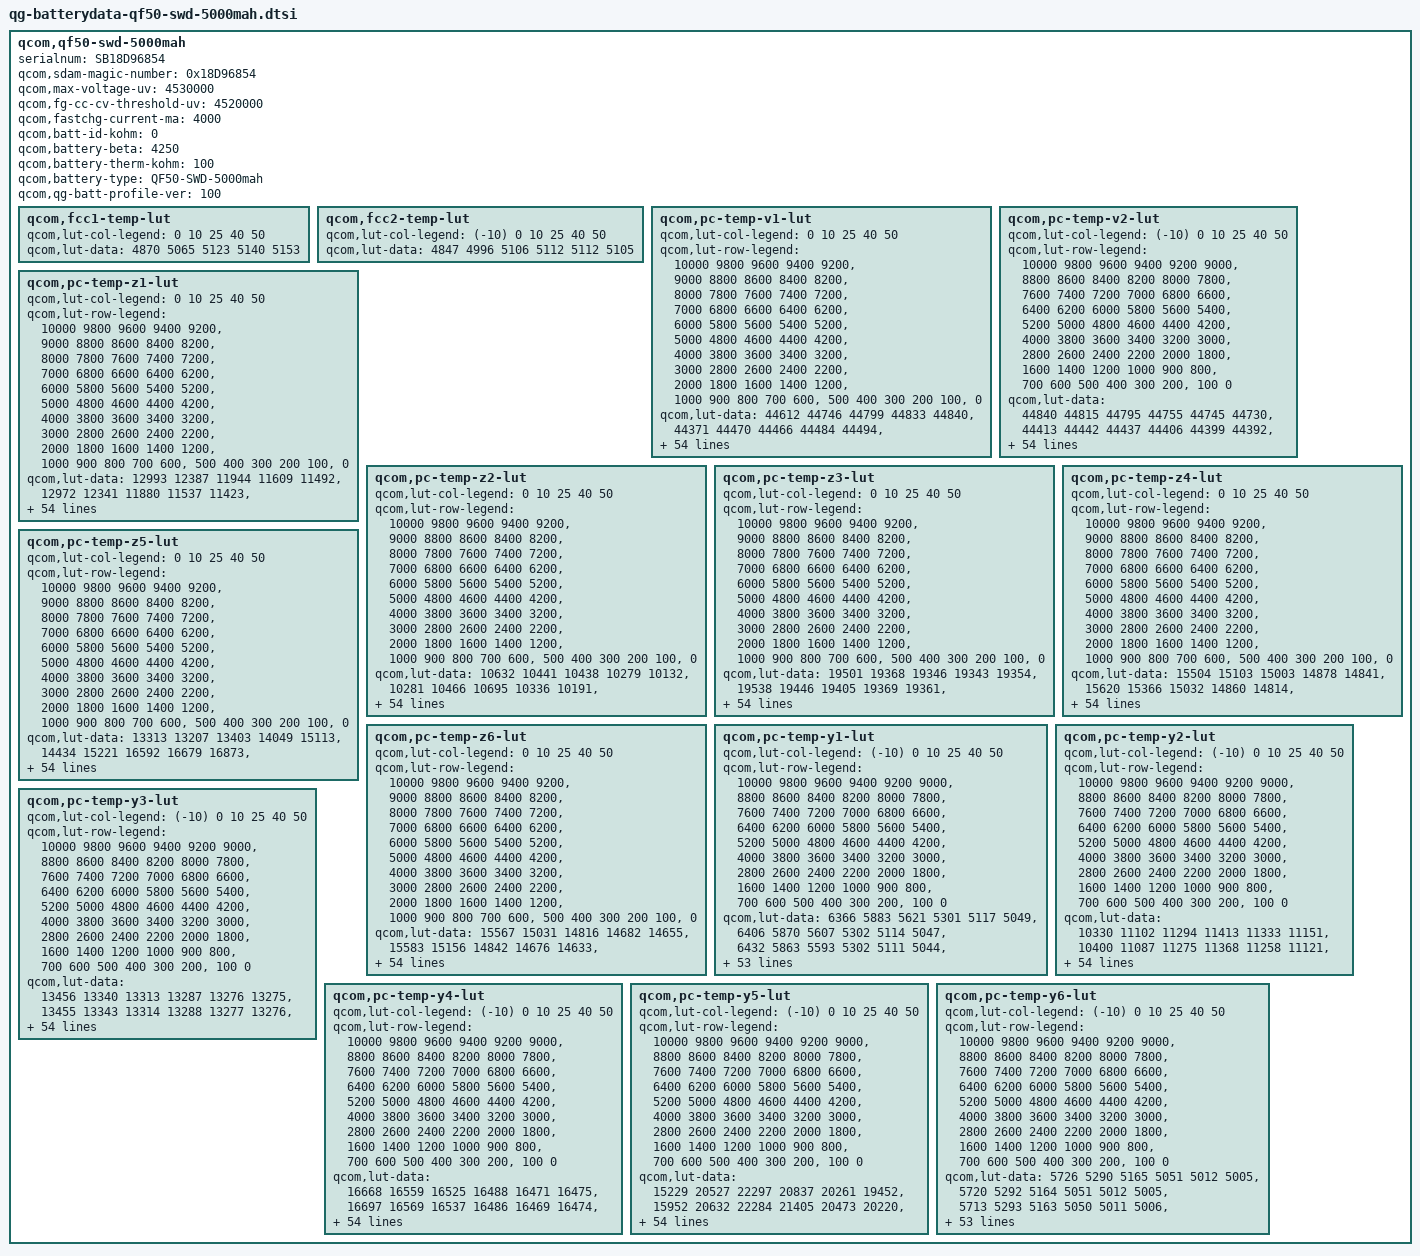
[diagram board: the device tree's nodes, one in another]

qcom,qf50-swd-5000mah {
    /* SWD_5000mAH_averaged_MasterSlave_Aug25th2023 */
    serialnum = "SB18D96854";
    qcom,sdam-magic-number = <0x18D96854>;
    qcom,max-voltage-uv = <4530000>;
    qcom,fg-cc-cv-threshold-uv = <4520000>;
    qcom,fastchg-current-ma = <4000>;
    qcom,batt-id-kohm = <0>;
    qcom,battery-beta = <4250>;
    qcom,battery-therm-kohm = <100>;
    qcom,battery-type = "QF50-SWD-5000mah";
    qcom,qg-batt-profile-ver = <100>;

	qcom,fcc1-temp-lut {
		qcom,lut-col-legend = <0 10 25 40 50>;
		qcom,lut-data = <4870 5065 5123 5140 5153>;
	};

	qcom,fcc2-temp-lut {
		qcom,lut-col-legend = <(-10) 0 10 25 40 50>;
		qcom,lut-data = <4847 4996 5106 5112 5112 5105>;
	};

	qcom,pc-temp-v1-lut {
		qcom,lut-col-legend = <0 10 25 40 50>;
		qcom,lut-row-legend = <10000 9800 9600 9400 9200>,
			<9000 8800 8600 8400 8200>,
			<8000 7800 7600 7400 7200>,
			<7000 6800 6600 6400 6200>,
			<6000 5800 5600 5400 5200>,
			<5000 4800 4600 4400 4200>,
			<4000 3800 3600 3400 3200>,
			<3000 2800 2600 2400 2200>,
			<2000 1800 1600 1400 1200>,
			<1000 900 800 700 600>,
			<500 400 300 200 100>,
			<0>;
		qcom,lut-data = <44612 44746 44799 44833 44840>,
			<44371 44470 44466 44484 44494>,
			<44146 44243 44222 44230 44237>,
			<43933 44027 44008 44012 44016>,
			<43716 43809 43792 43796 43800>,
			<43493 43592 43573 43580 43583>,
			<43265 43364 43348 43361 43363>,
			<43029 43123 43110 43127 43132>,
			<42785 42875 42862 42882 42891>,
			<42539 42623 42613 42633 42645>,
			<42294 42368 42359 42381 42393>,
			<42051 42118 42107 42129 42141>,
			<41813 41870 41857 41880 41891>,
			<41579 41627 41610 41632 41644>,
			<41353 41391 41373 41393 41405>,
			<41136 41161 41142 41158 41175>,
			<40927 40943 40918 40933 40950>,
			<40725 40736 40704 40719 40732>,
			<40532 40536 40499 40515 40521>,
			<40342 40344 40308 40322 40324>,
			<40160 40155 40130 40143 40144>,
			<39983 39958 39929 39944 39947>,
			<39793 39754 39680 39695 39700>,
			<39575 39537 39431 39444 39447>,
			<39354 39273 39217 39243 39253>,
			<39161 39028 39024 39069 39091>,
			<38983 38889 38886 38930 38950>,
			<38844 38795 38790 38819 38828>,
			<38746 38709 38704 38720 38717>,
			<38666 38620 38615 38620 38610>,
			<38591 38538 38530 38525 38511>,
			<38521 38461 38451 38438 38422>,
			<38458 38389 38377 38359 38346>,
			<38397 38324 38308 38285 38273>,
			<38341 38269 38245 38214 38202>,
			<38292 38218 38185 38146 38133>,
			<38253 38174 38129 38080 38061>,
			<38212 38134 38076 38016 37986>,
			<38164 38079 38010 37938 37898>,
			<38110 37995 37919 37833 37782>,
			<38037 37892 37811 37714 37650>,
			<37921 37771 37691 37597 37526>,
			<37788 37628 37551 37474 37397>,
			<37644 37458 37384 37313 37226>,
			<37482 37291 37222 37161 37079>,
			<37312 37169 37112 37064 37002>,
			<37238 37133 37076 37029 36971>,
			<37190 37103 37051 37005 36947>,
			<37144 37084 37029 36981 36923>,
			<37101 37047 36979 36924 36862>,
			<37066 36883 36754 36670 36593>,
			<37015 36451 36315 36222 36146>,
			<36854 35859 35711 35630 35559>,
			<36396 35022 34877 34819 34756>,
			<35545 33646 33564 33548 33505>,
			<30000 30000 30000 30000 30000>;
	};

	qcom,pc-temp-v2-lut {
		qcom,lut-col-legend = <(-10) 0 10 25 40 50>;
		qcom,lut-row-legend = <10000 9800 9600 9400 9200 9000>,
			<8800 8600 8400 8200 8000 7800>,
			<7600 7400 7200 7000 6800 6600>,
			<6400 6200 6000 5800 5600 5400>,
			<5200 5000 4800 4600 4400 4200>,
			<4000 3800 3600 3400 3200 3000>,
			<2800 2600 2400 2200 2000 1800>,
			<1600 1400 1200 1000 900 800>,
			<700 600 500 400 300 200>,
			<100 0>;
		qcom,lut-data = <44840 44815 44795 44755 44745 44730>,
			<44413 44442 44437 44406 44399 44392>,
			<44048 44119 44125 44100 44094 44091>,
			<43764 43861 43871 43845 43837 43837>,
			<43545 43657 43664 43634 43622 43622>,
			<43342 43455 43455 43420 43405 43407>,
			<43123 43234 43227 43189 43174 43178>,
			<42904 43008 42992 42951 42938 42943>,
			<42681 42772 42750 42705 42694 42699>,
			<42451 42524 42497 42452 42443 42446>,
			<42219 42276 42245 42198 42192 42194>,
			<41989 42030 41993 41946 41942 41944>,
			<41758 41785 41743 41696 41693 41697>,
			<41531 41545 41498 41453 41451 41456>,
			<41310 41310 41257 41215 41215 41223>,
			<41090 41081 41023 40983 40986 40994>,
			<40863 40865 40794 40758 40762 40770>,
			<40630 40653 40576 40541 40547 40554>,
			<40392 40429 40377 40338 40345 40349>,
			<40142 40191 40185 40141 40149 40151>,
			<39888 39946 39961 39941 39959 39961>,
			<39653 39687 39688 39741 39776 39783>,
			<39432 39430 39425 39529 39578 39590>,
			<39226 39211 39194 39275 39318 39338>,
			<39035 39017 38985 39021 39050 39072>,
			<38857 38846 38812 38837 38865 38884>,
			<38691 38693 38666 38696 38728 38745>,
			<38529 38556 38535 38572 38608 38622>,
			<38384 38426 38414 38461 38496 38507>,
			<38273 38305 38303 38360 38395 38402>,
			<38183 38195 38203 38265 38303 38309>,
			<38104 38094 38112 38176 38218 38224>,
			<38032 38003 38028 38094 38140 38144>,
			<37966 37927 37947 38021 38071 38072>,
			<37902 37864 37872 37951 38001 37998>,
			<37842 37808 37809 37880 37914 37904>,
			<37779 37760 37753 37809 37818 37794>,
			<37715 37716 37692 37729 37718 37683>,
			<37649 37659 37628 37637 37613 37572>,
			<37577 37592 37553 37540 37508 37462>,
			<37500 37509 37454 37445 37412 37367>,
			<37417 37393 37331 37343 37312 37271>,
			<37323 37255 37187 37213 37189 37148>,
			<37217 37114 37011 37067 37048 37001>,
			<37105 36960 36831 36924 36918 36868>,
			<36988 36795 36716 36861 36869 36821>,
			<36929 36726 36671 36841 36856 36808>,
			<36869 36669 36617 36820 36840 36791>,
			<36809 36612 36540 36784 36811 36761>,
			<36738 36515 36406 36703 36731 36673>,
			<36645 36346 36058 36414 36427 36347>,
			<36518 36138 35405 35887 35912 35836>,
			<36354 35618 34645 35179 35234 35164>,
			<36108 35142 33700 34152 34279 34213>,
			<35860 34625 32415 32677 32858 32764>,
			<35905 33809 29152 28152 28264 28690>;
	};

	qcom,pc-temp-z1-lut {
		qcom,lut-col-legend = <0 10 25 40 50>;
		qcom,lut-row-legend = <10000 9800 9600 9400 9200>,
			<9000 8800 8600 8400 8200>,
			<8000 7800 7600 7400 7200>,
			<7000 6800 6600 6400 6200>,
			<6000 5800 5600 5400 5200>,
			<5000 4800 4600 4400 4200>,
			<4000 3800 3600 3400 3200>,
			<3000 2800 2600 2400 2200>,
			<2000 1800 1600 1400 1200>,
			<1000 900 800 700 600>,
			<500 400 300 200 100>,
			<0>;
		qcom,lut-data = <12993 12387 11944 11609 11492>,
			<12972 12341 11880 11537 11423>,
			<12947 12311 11855 11516 11404>,
			<12920 12290 11826 11502 11393>,
			<12896 12267 11806 11491 11386>,
			<12866 12245 11792 11480 11379>,
			<12831 12225 11780 11471 11373>,
			<12806 12207 11767 11463 11370>,
			<12788 12190 11753 11457 11368>,
			<12770 12173 11743 11453 11367>,
			<12749 12157 11733 11452 11365>,
			<12729 12141 11727 11450 11364>,
			<12709 12124 11723 11448 11363>,
			<12685 12114 11721 11446 11362>,
			<12669 12114 11721 11446 11362>,
			<12665 12115 11723 11446 11362>,
			<12662 12116 11724 11446 11363>,
			<12658 12117 11725 11446 11364>,
			<12644 12118 11725 11448 11365>,
			<12635 12118 11726 11449 11367>,
			<12643 12118 11729 11451 11368>,
			<12664 12121 11731 11453 11369>,
			<12674 12129 11732 11453 11370>,
			<12675 12136 11734 11454 11371>,
			<12676 12144 11738 11455 11372>,
			<12680 12150 11744 11458 11374>,
			<12686 12150 11749 11461 11377>,
			<12690 12147 11752 11463 11379>,
			<12695 12145 11755 11466 11382>,
			<12700 12150 11760 11469 11385>,
			<12705 12158 11768 11473 11388>,
			<12717 12166 11774 11477 11391>,
			<12725 12175 11781 11482 11394>,
			<12715 12179 11787 11486 11397>,
			<12701 12180 11793 11492 11402>,
			<12701 12181 11798 11498 11407>,
			<12732 12187 11804 11504 11411>,
			<12761 12200 11809 11510 11415>,
			<12766 12213 11815 11516 11419>,
			<12766 12229 11823 11521 11424>,
			<12770 12241 11833 11527 11429>,
			<12786 12249 11844 11533 11432>,
			<12806 12257 11857 11539 11436>,
			<12832 12267 11866 11544 11439>,
			<12858 12284 11877 11551 11444>,
			<12851 12297 11881 11555 11446>,
			<12859 12284 11887 11555 11446>,
			<12862 12300 11898 11555 11447>,
			<12840 12296 11898 11559 11449>,
			<12864 12289 11901 11564 11453>,
			<12849 12305 11907 11570 11458>,
			<12880 12327 11922 11575 11462>,
			<12870 12331 11928 11582 11468>,
			<12924 12349 11941 11595 11479>,
			<12924 12349 11941 11595 11479>,
			<12924 12349 11941 11595 11479>;
	};

	qcom,pc-temp-z2-lut {
		qcom,lut-col-legend = <0 10 25 40 50>;
		qcom,lut-row-legend = <10000 9800 9600 9400 9200>,
			<9000 8800 8600 8400 8200>,
			<8000 7800 7600 7400 7200>,
			<7000 6800 6600 6400 6200>,
			<6000 5800 5600 5400 5200>,
			<5000 4800 4600 4400 4200>,
			<4000 3800 3600 3400 3200>,
			<3000 2800 2600 2400 2200>,
			<2000 1800 1600 1400 1200>,
			<1000 900 800 700 600>,
			<500 400 300 200 100>,
			<0>;
		qcom,lut-data = <10632 10441 10438 10279 10132>,
			<10281 10466 10695 10336 10191>,
			<10369 10561 10727 10521 10298>,
			<10428 10621 10695 10573 10465>,
			<10448 10605 10657 10589 10557>,
			<10429 10563 10610 10523 10527>,
			<10401 10527 10560 10432 10469>,
			<10381 10499 10512 10389 10411>,
			<10363 10475 10465 10358 10344>,
			<10347 10449 10433 10339 10316>,
			<10334 10427 10403 10322 10314>,
			<10324 10424 10389 10313 10313>,
			<10323 10433 10395 10324 10316>,
			<10325 10444 10407 10345 10323>,
			<10330 10454 10417 10350 10313>,
			<10343 10466 10427 10350 10246>,
			<10365 10536 10437 10349 10195>,
			<10382 10770 10446 10324 10203>,
			<10394 10892 10455 10288 10224>,
			<10404 10737 10464 10284 10245>,
			<10414 10544 10474 10297 10272>,
			<10424 10527 10497 10323 10312>,
			<10435 10537 10608 10510 10437>,
			<10447 10545 10708 10704 10572>,
			<10458 10555 10657 10632 10554>,
			<10467 10563 10523 10398 10443>,
			<10476 10559 10468 10317 10406>,
			<10480 10549 10467 10346 10623>,
			<10476 10546 10480 10384 10853>,
			<10472 10550 10507 10448 10888>,
			<10471 10555 10546 10548 10863>,
			<10474 10559 10575 10578 10754>,
			<10477 10564 10601 10556 10524>,
			<10482 10567 10617 10514 10344>,
			<10489 10568 10612 10438 10267>,
			<10494 10570 10599 10356 10213>,
			<10496 10573 10596 10342 10216>,
			<10497 10580 10596 10355 10274>,
			<10499 10588 10602 10378 10341>,
			<10501 10600 10635 10488 10399>,
			<10502 10607 10670 10599 10470>,
			<10502 10606 10682 10584 10606>,
			<10502 10603 10688 10538 10774>,
			<10508 10600 10671 10553 10717>,
			<10657 10649 10680 10556 10560>,
			<10620 10719 10674 10501 10432>,
			<10581 10706 10686 10490 10408>,
			<10554 10702 10650 10495 10411>,
			<10491 11125 10592 10515 10435>,
			<10392 11228 10633 10595 10526>,
			<10295 11060 10635 10516 10442>,
			<10109 10728 10652 10316 10170>,
			<9992 10608 10570 10203 10082>,
			<10053 10499 10489 10143 10022>,
			<10053 10499 10489 10143 10022>,
			<10053 10499 10489 10143 10022>;
	};

	qcom,pc-temp-z3-lut {
		qcom,lut-col-legend = <0 10 25 40 50>;
		qcom,lut-row-legend = <10000 9800 9600 9400 9200>,
			<9000 8800 8600 8400 8200>,
			<8000 7800 7600 7400 7200>,
			<7000 6800 6600 6400 6200>,
			<6000 5800 5600 5400 5200>,
			<5000 4800 4600 4400 4200>,
			<4000 3800 3600 3400 3200>,
			<3000 2800 2600 2400 2200>,
			<2000 1800 1600 1400 1200>,
			<1000 900 800 700 600>,
			<500 400 300 200 100>,
			<0>;
		qcom,lut-data = <19501 19368 19346 19343 19354>,
			<19538 19446 19405 19369 19361>,
			<19572 19482 19428 19395 19384>,
			<19609 19501 19437 19404 19393>,
			<19626 19508 19442 19408 19398>,
			<19632 19512 19447 19410 19402>,
			<19636 19514 19450 19412 19405>,
			<19636 19516 19452 19415 19406>,
			<19632 19516 19454 19418 19407>,
			<19629 19514 19452 19418 19408>,
			<19626 19509 19444 19413 19404>,
			<19623 19503 19435 19406 19398>,
			<19620 19495 19430 19402 19395>,
			<19616 19488 19425 19399 19392>,
			<19612 19484 19420 19395 19387>,
			<19604 19481 19414 19391 19381>,
			<19592 19481 19409 19387 19375>,
			<19585 19487 19405 19380 19370>,
			<19582 19490 19402 19373 19367>,
			<19579 19480 19398 19367 19362>,
			<19575 19468 19394 19360 19355>,
			<19572 19468 19393 19358 19352>,
			<19571 19471 19404 19364 19353>,
			<19580 19475 19415 19370 19356>,
			<19590 19479 19411 19364 19350>,
			<19593 19482 19398 19345 19333>,
			<19594 19481 19390 19337 19327>,
			<19594 19474 19385 19337 19350>,
			<19592 19471 19382 19339 19375>,
			<19587 19470 19383 19348 19386>,
			<19584 19471 19386 19364 19402>,
			<19580 19472 19390 19372 19402>,
			<19577 19474 19397 19377 19391>,
			<19576 19474 19401 19378 19380>,
			<19575 19473 19403 19374 19369>,
			<19574 19472 19405 19369 19357>,
			<19572 19470 19402 19363 19349>,
			<19569 19467 19396 19354 19340>,
			<19565 19464 19391 19350 19337>,
			<19560 19460 19389 19351 19336>,
			<19555 19456 19387 19352 19336>,
			<19550 19453 19384 19351 19338>,
			<19544 19450 19381 19350 19342>,
			<19532 19447 19378 19351 19351>,
			<19439 19435 19372 19351 19354>,
			<19401 19419 19364 19339 19341>,
			<19399 19412 19364 19337 19336>,
			<19322 19412 19361 19334 19325>,
			<19313 19316 19352 19327 19320>,
			<19311 19305 19347 19320 19310>,
			<19295 19319 19353 19336 19330>,
			<19284 19396 19349 19361 19351>,
			<19285 19383 19361 19364 19352>,
			<19334 19426 19382 19360 19350>,
			<19334 19426 19382 19360 19350>,
			<19334 19426 19382 19360 19350>;
	};

	qcom,pc-temp-z4-lut {
		qcom,lut-col-legend = <0 10 25 40 50>;
		qcom,lut-row-legend = <10000 9800 9600 9400 9200>,
			<9000 8800 8600 8400 8200>,
			<8000 7800 7600 7400 7200>,
			<7000 6800 6600 6400 6200>,
			<6000 5800 5600 5400 5200>,
			<5000 4800 4600 4400 4200>,
			<4000 3800 3600 3400 3200>,
			<3000 2800 2600 2400 2200>,
			<2000 1800 1600 1400 1200>,
			<1000 900 800 700 600>,
			<500 400 300 200 100>,
			<0>;
		qcom,lut-data = <15504 15103 15003 14878 14841>,
			<15620 15366 15032 14860 14814>,
			<15555 15260 15065 14909 14873>,
			<15384 15127 14993 14876 14847>,
			<15235 15041 14935 14843 14819>,
			<15133 14968 14892 14819 14800>,
			<15049 14910 14855 14798 14782>,
			<14985 14863 14823 14776 14765>,
			<14935 14826 14795 14756 14747>,
			<14893 14797 14772 14741 14735>,
			<14858 14774 14751 14731 14728>,
			<14827 14755 14736 14722 14723>,
			<14802 14737 14726 14715 14719>,
			<14780 14725 14719 14709 14716>,
			<14763 14719 14712 14704 14712>,
			<14751 14713 14705 14699 14709>,
			<14741 14703 14699 14694 14705>,
			<14736 14682 14694 14690 14702>,
			<14731 14672 14689 14686 14698>,
			<14729 14679 14684 14681 14693>,
			<14727 14690 14679 14675 14686>,
			<14725 14696 14679 14673 14683>,
			<14725 14703 14706 14704 14714>,
			<14739 14715 14746 14751 14764>,
			<14761 14762 14788 14789 14795>,
			<14780 14812 14832 14825 14820>,
			<14801 14813 14842 14834 14826>,
			<14809 14796 14829 14822 14791>,
			<14804 14779 14812 14803 14749>,
			<14795 14765 14796 14779 14726>,
			<14786 14752 14779 14749 14698>,
			<14778 14742 14761 14728 14686>,
			<14770 14733 14742 14708 14682>,
			<14765 14728 14726 14693 14678>,
			<14761 14724 14714 14684 14674>,
			<14757 14721 14704 14678 14670>,
			<14753 14718 14700 14675 14668>,
			<14747 14713 14698 14673 14666>,
			<14739 14710 14698 14673 14666>,
			<14727 14707 14701 14684 14680>,
			<14717 14703 14705 14695 14698>,
			<14708 14695 14703 14694 14694>,
			<14698 14684 14697 14688 14681>,
			<14683 14675 14694 14689 14685>,
			<14717 14659 14683 14684 14684>,
			<14756 14646 14665 14667 14660>,
			<14751 14644 14656 14664 14657>,
			<14832 14639 14644 14655 14652>,
			<14851 14740 14635 14634 14633>,
			<14849 14749 14633 14625 14625>,
			<14862 14735 14650 14649 14654>,
			<14873 14662 14671 14648 14661>,
			<14874 14686 14663 14652 14669>,
			<14850 14663 14649 14661 14676>,
			<14850 14663 14649 14661 14676>,
			<14850 14663 14649 14661 14676>;
	};

	qcom,pc-temp-z5-lut {
		qcom,lut-col-legend = <0 10 25 40 50>;
		qcom,lut-row-legend = <10000 9800 9600 9400 9200>,
			<9000 8800 8600 8400 8200>,
			<8000 7800 7600 7400 7200>,
			<7000 6800 6600 6400 6200>,
			<6000 5800 5600 5400 5200>,
			<5000 4800 4600 4400 4200>,
			<4000 3800 3600 3400 3200>,
			<3000 2800 2600 2400 2200>,
			<2000 1800 1600 1400 1200>,
			<1000 900 800 700 600>,
			<500 400 300 200 100>,
			<0>;
		qcom,lut-data = <13313 13207 13403 14049 15113>,
			<14434 15221 16592 16679 16873>,
			<15579 16599 17326 18067 18406>,
			<16715 17702 18125 19412 20281>,
			<17677 18476 18828 20393 21932>,
			<18518 19101 19382 20776 22942>,
			<19301 19868 19953 21148 23811>,
			<20019 20868 20728 22131 24878>,
			<20654 21829 21588 23632 26093>,
			<21393 22590 22245 24453 27076>,
			<22382 23273 22787 24989 27766>,
			<23549 24010 23336 25518 28394>,
			<24913 24929 24049 26271 29251>,
			<26962 25887 24806 27310 30194>,
			<28687 26681 25369 28456 30440>,
			<29334 27595 25890 29981 30240>,
			<29780 29937 26577 30962 30080>,
			<30324 35286 27858 31117 30991>,
			<31175 38212 29326 31196 32964>,
			<32065 36045 30261 31516 34713>,
			<32719 33235 31002 32338 36585>,
			<33376 34280 32794 33669 37422>,
			<34767 38251 43035 37493 37210>,
			<41528 41221 52368 41043 36676>,
			<48963 42862 47679 37077 32995>,
			<50242 43703 34918 25108 22664>,
			<49361 41565 28153 19588 18294>,
			<47961 35696 24825 18270 23040>,
			<45052 32668 23149 17696 28049>,
			<41893 32300 22989 19075 30762>,
			<41053 32506 23158 22191 35952>,
			<40746 33846 23952 23569 36677>,
			<40612 36812 26794 25459 35218>,
			<41448 39316 29967 27516 33611>,
			<43144 41515 34224 29770 31726>,
			<43668 42904 38322 31839 29972>,
			<43439 42967 39152 32309 29685>,
			<43114 42837 39090 32395 29773>,
			<42950 42667 38697 32615 29880>,
			<42923 42224 37751 34307 30085>,
			<42900 41653 36280 36065 30335>,
			<42849 40988 33786 33327 30345>,
			<42200 40309 30670 27249 30206>,
			<37984 40105 29474 27643 33552>,
			<27139 41604 29960 28411 36016>,
			<22167 39519 28888 24202 27578>,
			<27306 32777 30845 22823 23364>,
			<12627 32219 31255 22619 20396>,
			<12221 13721 27976 25098 23600>,
			<12190 12661 25949 25258 23098>,
			<11797 13341 24861 26244 26281>,
			<11620 22722 18709 28100 24475>,
			<11663 20909 21549 25076 20767>,
			<12783 31145 26214 19730 17364>,
			<12783 31145 26214 19730 17364>,
			<12783 31145 26214 19730 17364>;
	};

	qcom,pc-temp-z6-lut {
		qcom,lut-col-legend = <0 10 25 40 50>;
		qcom,lut-row-legend = <10000 9800 9600 9400 9200>,
			<9000 8800 8600 8400 8200>,
			<8000 7800 7600 7400 7200>,
			<7000 6800 6600 6400 6200>,
			<6000 5800 5600 5400 5200>,
			<5000 4800 4600 4400 4200>,
			<4000 3800 3600 3400 3200>,
			<3000 2800 2600 2400 2200>,
			<2000 1800 1600 1400 1200>,
			<1000 900 800 700 600>,
			<500 400 300 200 100>,
			<0>;
		qcom,lut-data = <15567 15031 14816 14682 14655>,
			<15583 15156 14842 14676 14633>,
			<15553 15108 14860 14705 14665>,
			<15464 15047 14828 14693 14657>,
			<15383 15002 14801 14681 14649>,
			<15321 14962 14781 14670 14642>,
			<15267 14928 14763 14661 14635>,
			<15223 14901 14747 14652 14629>,
			<15184 14877 14733 14645 14622>,
			<15151 14856 14718 14637 14616>,
			<15121 14838 14703 14629 14611>,
			<15095 14822 14691 14622 14605>,
			<15072 14807 14683 14617 14601>,
			<15051 14796 14677 14612 14598>,
			<15034 14790 14670 14607 14593>,
			<15018 14785 14664 14602 14588>,
			<15005 14780 14659 14597 14583>,
			<14998 14775 14654 14591 14579>,
			<14994 14772 14650 14586 14575>,
			<14992 14770 14646 14580 14570>,
			<14992 14769 14642 14574 14563>,
			<14992 14770 14642 14572 14560>,
			<14992 14776 14660 14590 14576>,
			<15004 14785 14684 14613 14599>,
			<15022 14809 14699 14623 14605>,
			<15035 14833 14712 14630 14609>,
			<15046 14833 14714 14632 14609>,
			<15050 14825 14707 14627 14607>,
			<15048 14818 14699 14621 14603>,
			<15045 14813 14694 14616 14600>,
			<15042 14809 14689 14613 14597>,
			<15039 14807 14685 14608 14592>,
			<15037 14806 14681 14603 14586>,
			<15036 14805 14679 14598 14579>,
			<15036 14805 14676 14593 14572>,
			<15036 14804 14674 14589 14565>,
			<15037 14804 14672 14584 14559>,
			<15038 14805 14669 14580 14555>,
			<15040 14806 14669 14578 14553>,
			<15042 14807 14671 14583 14559>,
			<15044 14808 14674 14589 14566>,
			<15047 14807 14674 14589 14566>,
			<15049 14806 14672 14587 14566>,
			<15051 14807 14672 14589 14571>,
			<15039 14802 14668 14588 14572>,
			<15043 14794 14660 14575 14555>,
			<15045 14789 14656 14573 14551>,
			<15039 14788 14650 14566 14544>,
			<15044 14784 14642 14555 14533>,
			<15047 14787 14642 14548 14524>,
			<15045 14793 14656 14568 14547>,
			<15052 14808 14666 14583 14565>,
			<15069 14818 14674 14589 14571>,
			<15089 14842 14686 14594 14577>,
			<15089 14842 14686 14594 14577>,
			<15089 14842 14686 14594 14577>;
	};

	qcom,pc-temp-y1-lut {
		qcom,lut-col-legend = <(-10) 0 10 25 40 50>;
		qcom,lut-row-legend = <10000 9800 9600 9400 9200 9000>,
			<8800 8600 8400 8200 8000 7800>,
			<7600 7400 7200 7000 6800 6600>,
			<6400 6200 6000 5800 5600 5400>,
			<5200 5000 4800 4600 4400 4200>,
			<4000 3800 3600 3400 3200 3000>,
			<2800 2600 2400 2200 2000 1800>,
			<1600 1400 1200 1000 900 800>,
			<700 600 500 400 300 200>,
			<100 0>;
		qcom,lut-data = <6366 5883 5621 5301 5117 5049>,
			<6406 5870 5607 5302 5114 5047>,
			<6432 5863 5593 5302 5111 5044>,
			<6447 5861 5582 5300 5108 5042>,
			<6453 5861 5573 5297 5105 5040>,
			<6452 5864 5571 5294 5102 5038>,
			<6443 5873 5574 5289 5099 5037>,
			<6423 5884 5578 5283 5096 5035>,
			<6404 5885 5575 5279 5093 5034>,
			<6386 5874 5563 5274 5090 5033>,
			<6372 5865 5556 5270 5088 5032>,
			<6372 5856 5557 5266 5087 5031>,
			<6377 5846 5559 5263 5085 5031>,
			<6380 5845 5557 5261 5084 5031>,
			<6378 5851 5554 5260 5083 5031>,
			<6377 5854 5550 5259 5082 5031>,
			<6382 5852 5540 5259 5084 5031>,
			<6404 5848 5532 5260 5085 5031>,
			<6418 5848 5534 5260 5085 5031>,
			<6412 5850 5538 5260 5084 5032>,
			<6401 5852 5541 5261 5084 5033>,
			<6392 5865 5544 5263 5085 5034>,
			<6383 5883 5546 5266 5086 5035>,
			<6377 5884 5546 5269 5088 5036>,
			<6379 5875 5546 5272 5091 5037>,
			<6384 5869 5546 5276 5093 5039>,
			<6389 5871 5547 5282 5095 5040>,
			<6391 5876 5549 5286 5097 5042>,
			<6393 5878 5552 5288 5100 5044>,
			<6387 5880 5557 5290 5102 5046>,
			<6369 5883 5561 5294 5105 5049>,
			<6359 5884 5564 5300 5108 5051>,
			<6370 5885 5567 5306 5111 5053>,
			<6387 5887 5571 5312 5115 5056>,
			<6390 5891 5574 5319 5118 5058>,
			<6388 5892 5576 5323 5121 5061>,
			<6386 5889 5578 5327 5124 5063>,
			<6379 5882 5581 5330 5126 5065>,
			<6368 5879 5590 5333 5128 5067>,
			<6360 5878 5599 5335 5130 5068>,
			<6360 5879 5608 5337 5133 5070>,
			<6362 5885 5618 5339 5136 5072>,
			<6365 5891 5618 5341 5137 5073>,
			<6364 5900 5618 5350 5139 5074>,
			<6358 5902 5630 5354 5143 5078>,
			<6367 5894 5633 5364 5149 5081>,
			<6389 5922 5626 5367 5149 5081>,
			<6423 5930 5658 5379 5148 5080>,
			<6468 5997 5634 5375 5149 5081>,
			<6540 6066 5705 5380 5149 5082>,
			<6619 6074 5776 5384 5150 5083>,
			<6696 5962 5736 5393 5156 5088>,
			<6846 5943 5589 5420 5164 5093>,
			<7079 5943 5285 5458 5172 5101>,
			<7079 5943 5285 5458 5172 5101>,
			<7079 5943 5285 5458 5172 5101>;
	};

	qcom,pc-temp-y2-lut {
		qcom,lut-col-legend = <(-10) 0 10 25 40 50>;
		qcom,lut-row-legend = <10000 9800 9600 9400 9200 9000>,
			<8800 8600 8400 8200 8000 7800>,
			<7600 7400 7200 7000 6800 6600>,
			<6400 6200 6000 5800 5600 5400>,
			<5200 5000 4800 4600 4400 4200>,
			<4000 3800 3600 3400 3200 3000>,
			<2800 2600 2400 2200 2000 1800>,
			<1600 1400 1200 1000 900 800>,
			<700 600 500 400 300 200>,
			<100 0>;
		qcom,lut-data = <10330 11102 11294 11413 11333 11151>,
			<10400 11087 11275 11368 11258 11121>,
			<10474 11072 11253 11323 11162 11089>,
			<10546 11057 11229 11278 11064 11053>,
			<10607 11044 11204 11235 10982 11017>,
			<10652 11031 11177 11194 10935 10980>,
			<10678 11019 11148 11151 10907 10940>,
			<10696 11007 11119 11112 10887 10900>,
			<10710 10993 11094 11080 10882 10862>,
			<10720 10974 11072 11049 10876 10824>,
			<10729 10965 11061 11039 10871 10792>,
			<10742 10967 11059 11058 10857 10763>,
			<10759 10974 11059 11082 10844 10743>,
			<10780 10986 11068 11096 10850 10743>,
			<10809 11012 11092 11110 10870 10751>,
			<10841 11043 11118 11133 10886 10756>,
			<10869 11076 11149 11180 10897 10759>,
			<10897 11109 11187 11232 10914 10764>,
			<10914 11128 11243 11288 10950 10787>,
			<10919 11145 11305 11347 11018 10844>,
			<10922 11153 11315 11376 11137 10945>,
			<10923 11158 11286 11404 11403 11188>,
			<10917 11169 11266 11419 11561 11344>,
			<10909 11180 11277 11366 11412 11270>,
			<10898 11193 11300 11284 11185 11146>,
			<10880 11205 11321 11272 11147 11118>,
			<10858 11218 11347 11280 11147 11119>,
			<10831 11230 11359 11292 11149 11126>,
			<10785 11230 11360 11327 11201 11156>,
			<10597 11219 11360 11377 11269 11208>,
			<10114 11210 11366 11424 11288 11266>,
			<9821 11205 11385 11471 11295 11339>,
			<9776 11197 11392 11508 11320 11380>,
			<9750 11162 11379 11538 11425 11403>,
			<9730 11041 11355 11556 11520 11418>,
			<9713 10958 11329 11549 11491 11408>,
			<9701 10949 11291 11528 11401 11379>,
			<9692 10945 11249 11505 11353 11347>,
			<9685 10911 11204 11470 11328 11264>,
			<9680 10836 11146 11444 11312 11183>,
			<9675 10714 11056 11445 11319 11169>,
			<9671 10271 10934 11448 11325 11173>,
			<9668 9814 10803 11385 11258 11167>,
			<9666 9724 10441 11338 11204 11125>,
			<9663 9688 10088 11206 11146 10981>,
			<9660 9672 9889 11157 10973 10822>,
			<9658 9664 9757 11187 10959 10801>,
			<9656 9658 9689 11206 11004 10785>,
			<9653 9651 9662 11215 11035 10831>,
			<9650 9649 9652 11212 11033 10867>,
			<9649 9648 9650 11090 10896 10750>,
			<9648 9648 9649 10944 10858 10703>,
			<9648 9648 9649 10736 10735 10610>,
			<9648 9649 9649 10355 10628 10470>,
			<9648 9649 9649 10355 10628 10470>,
			<9648 9649 9649 10355 10628 10470>;
	};

	qcom,pc-temp-y3-lut {
		qcom,lut-col-legend = <(-10) 0 10 25 40 50>;
		qcom,lut-row-legend = <10000 9800 9600 9400 9200 9000>,
			<8800 8600 8400 8200 8000 7800>,
			<7600 7400 7200 7000 6800 6600>,
			<6400 6200 6000 5800 5600 5400>,
			<5200 5000 4800 4600 4400 4200>,
			<4000 3800 3600 3400 3200 3000>,
			<2800 2600 2400 2200 2000 1800>,
			<1600 1400 1200 1000 900 800>,
			<700 600 500 400 300 200>,
			<100 0>;
		qcom,lut-data = <13456 13340 13313 13287 13276 13275>,
			<13455 13343 13314 13288 13277 13276>,
			<13454 13346 13315 13289 13278 13277>,
			<13453 13349 13316 13290 13279 13278>,
			<13451 13351 13317 13291 13280 13279>,
			<13450 13353 13318 13292 13281 13280>,
			<13449 13355 13319 13294 13282 13281>,
			<13447 13356 13320 13295 13282 13282>,
			<13446 13357 13321 13295 13283 13282>,
			<13444 13357 13321 13296 13285 13282>,
			<13441 13357 13322 13296 13286 13282>,
			<13438 13357 13323 13297 13286 13283>,
			<13435 13357 13323 13297 13287 13284>,
			<13432 13357 13324 13298 13288 13286>,
			<13430 13355 13323 13299 13289 13288>,
			<13428 13354 13323 13300 13290 13289>,
			<13424 13354 13320 13300 13291 13289>,
			<13420 13354 13319 13299 13292 13289>,
			<13415 13353 13319 13298 13294 13290>,
			<13409 13350 13320 13296 13295 13291>,
			<13401 13346 13320 13296 13295 13291>,
			<13395 13342 13316 13296 13294 13291>,
			<13391 13336 13312 13296 13292 13292>,
			<13386 13333 13309 13294 13286 13287>,
			<13382 13331 13307 13290 13279 13279>,
			<13378 13329 13306 13287 13278 13278>,
			<13373 13328 13305 13285 13279 13278>,
			<13360 13327 13304 13285 13279 13279>,
			<13350 13325 13303 13286 13278 13278>,
			<13348 13323 13302 13287 13278 13277>,
			<13349 13321 13302 13287 13277 13277>,
			<13351 13318 13302 13287 13277 13277>,
			<13356 13315 13302 13287 13277 13277>,
			<13367 13313 13302 13286 13279 13278>,
			<13378 13312 13302 13286 13280 13278>,
			<13392 13312 13302 13286 13280 13279>,
			<13409 13318 13302 13286 13280 13279>,
			<13428 13328 13303 13286 13280 13279>,
			<13452 13333 13305 13286 13280 13279>,
			<13481 13337 13306 13285 13280 13279>,
			<13521 13342 13308 13286 13280 13280>,
			<13570 13346 13310 13286 13281 13282>,
			<13630 13353 13314 13286 13281 13281>,
			<13710 13380 13314 13286 13279 13278>,
			<13826 13433 13315 13284 13276 13277>,
			<14029 13508 13336 13288 13284 13283>,
			<14207 13638 13370 13292 13288 13285>,
			<14479 13977 13446 13297 13290 13287>,
			<15162 15483 13736 13301 13292 13289>,
			<17129 20449 15668 13305 13292 13288>,
			<21974 38063 24097 13303 13287 13286>,
			<34693 65535 56968 13306 13287 13285>,
			<65535 65535 65535 13315 13289 13289>,
			<65535 65535 65535 13349 13298 13294>,
			<65535 65535 65535 13349 13298 13294>,
			<65535 65535 65535 13349 13298 13294>;
	};

	qcom,pc-temp-y4-lut {
		qcom,lut-col-legend = <(-10) 0 10 25 40 50>;
		qcom,lut-row-legend = <10000 9800 9600 9400 9200 9000>,
			<8800 8600 8400 8200 8000 7800>,
			<7600 7400 7200 7000 6800 6600>,
			<6400 6200 6000 5800 5600 5400>,
			<5200 5000 4800 4600 4400 4200>,
			<4000 3800 3600 3400 3200 3000>,
			<2800 2600 2400 2200 2000 1800>,
			<1600 1400 1200 1000 900 800>,
			<700 600 500 400 300 200>,
			<100 0>;
		qcom,lut-data = <16668 16559 16525 16488 16471 16475>,
			<16697 16569 16537 16486 16469 16474>,
			<16747 16591 16548 16484 16467 16473>,
			<16805 16616 16556 16482 16465 16472>,
			<16854 16636 16562 16480 16464 16471>,
			<16881 16645 16564 16479 16463 16471>,
			<16886 16644 16562 16479 16463 16470>,
			<16888 16644 16558 16478 16464 16470>,
			<16888 16642 16554 16479 16464 16469>,
			<16881 16636 16549 16482 16464 16468>,
			<16873 16632 16547 16485 16465 16468>,
			<16873 16634 16549 16489 16468 16469>,
			<16876 16640 16551 16494 16472 16470>,
			<16879 16648 16556 16499 16475 16472>,
			<16882 16662 16568 16507 16479 16474>,
			<16885 16680 16582 16516 16483 16477>,
			<16884 16705 16603 16529 16489 16481>,
			<16870 16728 16627 16544 16496 16485>,
			<16851 16731 16657 16568 16504 16491>,
			<16820 16720 16687 16594 16514 16498>,
			<16777 16702 16687 16605 16530 16511>,
			<16740 16663 16640 16609 16562 16540>,
			<16707 16609 16586 16609 16580 16558>,
			<16677 16577 16543 16559 16539 16528>,
			<16649 16554 16507 16484 16476 16478>,
			<16623 16539 16496 16470 16463 16464>,
			<16606 16531 16491 16469 16462 16461>,
			<16595 16524 16489 16469 16461 16460>,
			<16588 16518 16489 16473 16467 16463>,
			<16594 16510 16490 16481 16476 16470>,
			<16618 16506 16491 16488 16486 16477>,
			<16636 16504 16493 16496 16497 16487>,
			<16641 16502 16494 16503 16506 16496>,
			<16644 16504 16492 16513 16515 16508>,
			<16647 16516 16489 16520 16520 16516>,
			<16651 16525 16492 16520 16517 16513>,
			<16656 16530 16500 16517 16507 16502>,
			<16661 16535 16508 16512 16496 16492>,
			<16667 16541 16518 16496 16483 16483>,
			<16672 16550 16524 16484 16474 16478>,
			<16677 16559 16523 16486 16478 16484>,
			<16681 16572 16520 16489 16482 16493>,
			<16681 16583 16519 16487 16480 16490>,
			<16681 16586 16522 16481 16466 16472>,
			<16683 16584 16519 16460 16444 16441>,
			<16685 16589 16535 16474 16457 16462>,
			<16686 16600 16556 16489 16481 16498>,
			<16690 16607 16587 16511 16517 16538>,
			<16731 16705 16640 16542 16554 16574>,
			<16977 17408 16876 16575 16570 16582>,
			<17741 21347 20034 16542 16499 16493>,
			<20756 37147 42728 16520 16475 16480>,
			<40431 39078 65535 16547 16479 16478>,
			<65535 59865 65535 16609 16483 16478>,
			<65535 59865 65535 16609 16483 16478>,
			<65535 59865 65535 16609 16483 16478>;
	};

	qcom,pc-temp-y5-lut {
		qcom,lut-col-legend = <(-10) 0 10 25 40 50>;
		qcom,lut-row-legend = <10000 9800 9600 9400 9200 9000>,
			<8800 8600 8400 8200 8000 7800>,
			<7600 7400 7200 7000 6800 6600>,
			<6400 6200 6000 5800 5600 5400>,
			<5200 5000 4800 4600 4400 4200>,
			<4000 3800 3600 3400 3200 3000>,
			<2800 2600 2400 2200 2000 1800>,
			<1600 1400 1200 1000 900 800>,
			<700 600 500 400 300 200>,
			<100 0>;
		qcom,lut-data = <15229 20527 22297 20837 20261 19452>,
			<15952 20632 22284 21405 20473 20220>,
			<16642 20784 22181 21696 20590 21231>,
			<17289 20949 22026 21774 20632 22238>,
			<17885 21097 21857 21702 20618 22995>,
			<18421 21196 21710 21544 20566 23257>,
			<18944 21286 21490 21232 20159 23179>,
			<19420 21372 21178 20760 19633 22996>,
			<19632 21294 20815 20069 19390 22319>,
			<19710 20715 20337 19024 19068 20545>,
			<19756 20063 19854 18173 18736 19327>,
			<19755 19503 19396 17533 18004 18616>,
			<19704 18959 18908 17054 17273 18183>,
			<19700 18583 18281 16687 17073 18404>,
			<20087 18273 17534 16248 17073 19018>,
			<20761 18135 17016 15956 17055 19166>,
			<21433 18680 16550 15384 16658 18407>,
			<22242 19832 16280 14919 16279 17477>,
			<22726 21011 17092 14849 16167 16798>,
			<22797 22506 19120 14840 16073 16210>,
			<22828 23389 20936 15487 16199 16190>,
			<22914 23527 22790 19353 17247 17047>,
			<23208 23609 24086 22589 18474 18229>,
			<23432 23759 24692 23703 19691 20033>,
			<23332 24076 25091 24379 20728 21906>,
			<22965 24298 25190 23882 20795 22120>,
			<22296 24489 25095 21354 20350 21606>,
			<19326 24660 24912 20015 19717 20886>,
			<15808 24443 24469 20608 18383 18970>,
			<14302 23743 24024 21331 17050 16828>,
			<13366 22754 24411 21403 16737 16412>,
			<12956 20828 25868 21379 16609 16300>,
			<12951 18527 26578 21382 16680 16289>,
			<13061 17542 26256 21560 18059 16973>,
			<13172 17065 25876 21898 19795 18138>,
			<13320 17005 25595 22708 20826 19524>,
			<13462 19290 24790 24025 21717 21210>,
			<13571 22682 24476 24352 21934 21820>,
			<13673 23562 24569 23511 21872 21840>,
			<13788 23786 24652 22669 21762 21867>,
			<13936 23866 24324 22262 21468 22343>,
			<14048 19842 23621 21961 21177 23485>,
			<14023 15072 22881 21833 22580 25442>,
			<13859 14526 19324 21912 22813 24652>,
			<13651 14575 15773 20591 18684 19727>,
			<13509 13281 14967 19987 19071 18699>,
			<13399 13017 15018 19193 19012 16852>,
			<13091 13515 14789 19419 17804 15759>,
			<12439 12420 14079 19243 16898 15326>,
			<11152 10343 12453 19510 16729 15100>,
			<9973 9283 9692 19365 16578 16448>,
			<9289 9090 8925 21070 17292 15658>,
			<8942 9444 8815 19619 16674 15782>,
			<10397 17589 8744 17676 20905 17405>,
			<10397 17589 8744 17676 20905 17405>,
			<10397 17589 8744 17676 20905 17405>;
	};

	qcom,pc-temp-y6-lut {
		qcom,lut-col-legend = <(-10) 0 10 25 40 50>;
		qcom,lut-row-legend = <10000 9800 9600 9400 9200 9000>,
			<8800 8600 8400 8200 8000 7800>,
			<7600 7400 7200 7000 6800 6600>,
			<6400 6200 6000 5800 5600 5400>,
			<5200 5000 4800 4600 4400 4200>,
			<4000 3800 3600 3400 3200 3000>,
			<2800 2600 2400 2200 2000 1800>,
			<1600 1400 1200 1000 900 800>,
			<700 600 500 400 300 200>,
			<100 0>;
		qcom,lut-data = <5726 5290 5165 5051 5012 5005>,
			<5720 5292 5164 5051 5012 5005>,
			<5713 5293 5163 5050 5011 5006>,
			<5706 5293 5161 5049 5011 5006>,
			<5698 5292 5159 5048 5011 5007>,
			<5690 5291 5157 5048 5012 5007>,
			<5682 5289 5153 5048 5012 5008>,
			<5673 5285 5150 5048 5013 5008>,
			<5663 5280 5146 5048 5013 5008>,
			<5650 5276 5142 5048 5014 5008>,
			<5639 5272 5140 5049 5015 5008>,
			<5633 5270 5139 5050 5016 5009>,
			<5628 5268 5139 5051 5017 5010>,
			<5624 5268 5139 5053 5019 5011>,
			<5620 5269 5141 5056 5021 5013>,
			<5616 5271 5143 5058 5023 5015>,
			<5611 5276 5146 5062 5025 5017>,
			<5605 5282 5151 5065 5028 5018>,
			<5598 5283 5159 5071 5031 5020>,
			<5586 5278 5168 5078 5035 5022>,
			<5571 5270 5168 5081 5040 5027>,
			<5559 5257 5152 5082 5047 5035>,
			<5549 5240 5134 5082 5051 5040>,
			<5541 5230 5120 5067 5036 5027>,
			<5535 5222 5109 5042 5012 5007>,
			<5531 5219 5106 5037 5008 5003>,
			<5528 5219 5106 5036 5008 5002>,
			<5526 5220 5105 5036 5008 5002>,
			<5525 5220 5106 5038 5010 5003>,
			<5528 5221 5107 5042 5012 5004>,
			<5540 5221 5109 5045 5015 5006>,
			<5555 5223 5112 5048 5018 5009>,
			<5573 5227 5115 5051 5021 5013>,
			<5593 5233 5116 5054 5025 5017>,
			<5615 5242 5118 5057 5028 5020>,
			<5638 5255 5122 5058 5027 5019>,
			<5664 5271 5129 5058 5025 5016>,
			<5694 5292 5136 5058 5022 5014>,
			<5730 5314 5145 5054 5018 5012>,
			<5771 5339 5155 5051 5016 5010>,
			<5817 5367 5165 5052 5018 5013>,
			<5871 5397 5178 5055 5020 5017>,
			<5935 5433 5196 5056 5019 5016>,
			<6015 5490 5220 5056 5015 5009>,
			<6129 5575 5246 5049 5007 5000>,
			<6321 5700 5323 5061 5017 5011>,
			<6491 5850 5405 5069 5026 5023>,
			<6748 6187 5545 5081 5039 5036>,
			<7368 7507 5901 5094 5051 5048>,
			<9029 11388 7575 5108 5056 5049>,
			<12822 24602 14648 5100 5032 5022>,
			<22524 65535 43420 5103 5025 5019>,
			<50538 65535 65535 5138 5030 5022>,
			<65535 65535 65535 5229 5039 5028>,
			<65535 65535 65535 5229 5039 5028>,
			<65535 65535 65535 5229 5039 5028>;
	};

};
